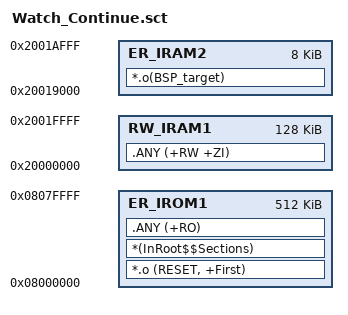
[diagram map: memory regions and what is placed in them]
; *************************************************************
; *** Scatter-Loading Description File generated by uVision ***
; *************************************************************

LR_IROM1 0x08000000 0x00080000  {    ; load region size_region
  ER_IROM1 0x08000000 0x00080000  {  ; load address = execution address
   
   *.o (RESET, +First)
   *(InRoot$$Sections)
   .ANY (+RO)
}
  RW_IRAM1 0x20000000 0x00020000  {  ; RW data
   .ANY (+RW +ZI)
;   *.o (BSP_target)  
  }
}

;LR_IROM2 0x08007000 0x00001000  {
;	ER_IROM2 0x08007000 0x00001000  {  ; load address = execution address
		
;  }
;}

LR_IRAM2 0x08007000 0x00001000  {; load address 
	ER_IRAM2 0x20019000 0x00002000   {  
		*.o(BSP_target)

  }
}
